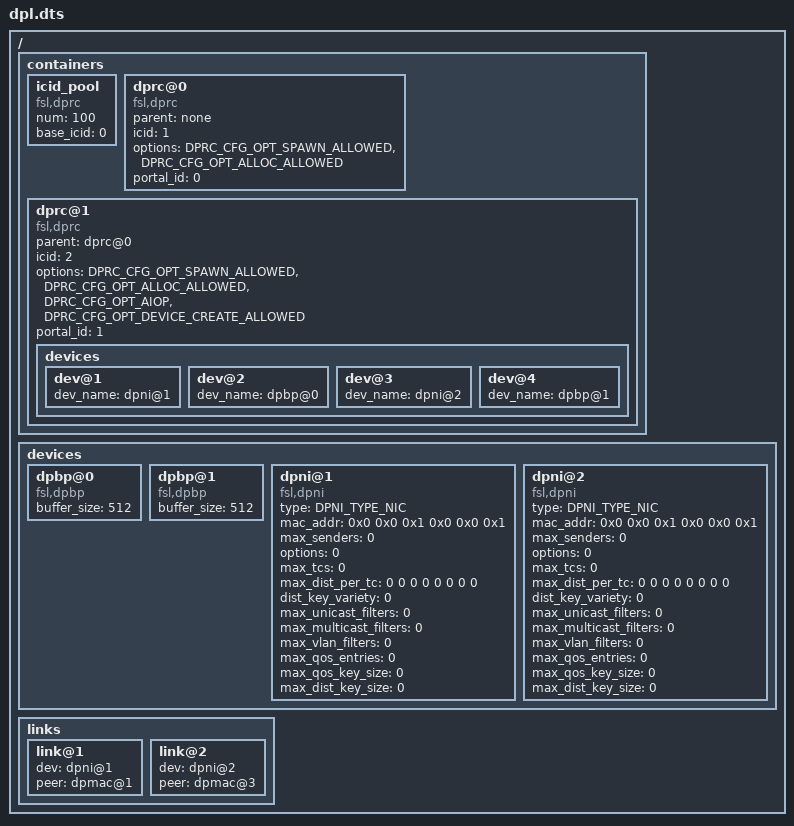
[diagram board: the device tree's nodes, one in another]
/dts-v1/;
/***************************************************************************
Example Layout:
Layout is built from 3 different sections: containers, devices, links.

1. containers - all containers are represented as : dprc@<id>.
	1.1 Container node contains:
		1.1.1 Properties required for its initialization: 
			compatible = "fsl,dprc";
			parent = "dprc@<id>"; or "none" if this is a root-level container
			options =  "string";	one or more of the following options: 
							“DPRC_CFG_OPT_SPAWN_ALLOWED”
							“DPRC_CFG_OPT_ALLOC_ALLOWED”
							“DPRC_CFG_OPT_DEVICE_CREATE_ALLOWED”
							“DPRC_CFG_OPT_TOPOLOGY_CHANGES_ALLOWED”
							“DPRC_CFG_OPT_IOMMU_BYPASS”
							“DPRC_CFG_OPT_AIOP”

			portal_id = <int>;
		1.1.2 resources - all resources are defined as follows:
			type = "string";	one of resource type defines;
			num = <int>;		Number of resources;
			options = <int>; 	Request options
			id_base_align = <int>;  In case of explicit assignment, this field represents the required base ID for resource allocation;
						In case of non-explicit assignment, this field indicates the required alignment for the resource ID(s) - use 0 or 1 if there is no alignment requirement.
		1.1.3 devices - all devices' children are built as follows:
			dev_name = "<dev>@<id>";
			portal_id = <int>;
2. devices - 	all devices' children are named: <dev>@<id> and contains all parameters required for initialization.
3. links - 	all links' children are representing two devices linked to each other. 
		
****************************************************************************/
/ {	
	containers {
		icid_pool {
			compatible = "fsl,dprc";
			num = <100>;
			base_icid = <0>;
		};
		dprc@0 {
			compatible = "fsl,dprc";
			parent = "none"; 
			icid = <1>;
			options = "DPRC_CFG_OPT_SPAWN_ALLOWED" , "DPRC_CFG_OPT_ALLOC_ALLOWED";
			portal_id = <0>;
		};
		dprc@1 {
			compatible = "fsl,dprc";
			parent = "dprc@0"; 
			icid = <2>;
			options = "DPRC_CFG_OPT_SPAWN_ALLOWED" , "DPRC_CFG_OPT_ALLOC_ALLOWED" , "DPRC_CFG_OPT_AIOP" , "DPRC_CFG_OPT_DEVICE_CREATE_ALLOWED";
			portal_id = <1>;
			devices {
				dev@1{
					dev_name = "dpni@1";
				};
				dev@2{
					dev_name = "dpbp@0";
				};
				dev@3{
					dev_name = "dpni@2";
				};
                                dev@4{
                                        dev_name = "dpbp@1";
                                };

			};
		};
	};
	devices {
                dpbp@0 {
                        compatible = "fsl,dpbp";
                        buffer_size = <512>;
                };
		dpbp@1 {
			compatible = "fsl,dpbp";
			buffer_size = <512>;
		};
		dpni@1{
			compatible = "fsl,dpni";
			type = "DPNI_TYPE_NIC";
			mac_addr = < 0x0 0x0 0x1 0x0 0x0 0x1 >;				
			max_senders = <0>;
			options = <0>;
			max_tcs = <0>;
			max_dist_per_tc = < 0 0 0 0 0 0 0 0 >; 		
			dist_key_variety = <0>;
			max_unicast_filters = <0>;
			max_multicast_filters = <0>;
			max_vlan_filters = <0>;
			max_qos_entries = <0>;
			max_qos_key_size = <0>;
			max_dist_key_size = <0>;
		};
		dpni@2{
			compatible = "fsl,dpni";
			type = "DPNI_TYPE_NIC";
			mac_addr = < 0x0 0x0 0x1 0x0 0x0 0x1 >;				
			max_senders = <0>;
			options = <0>;
			max_tcs = <0>;
			max_dist_per_tc = < 0 0 0 0 0 0 0 0 >; 		
			dist_key_variety = <0>;
			max_unicast_filters = <0>;
			max_multicast_filters = <0>;
			max_vlan_filters = <0>;
			max_qos_entries = <0>;
			max_qos_key_size = <0>;
			max_dist_key_size = <0>;
		};
	};
	links {
		link@1 {
			dev = "dpni@1";
			peer = "dpmac@1";
		};
		link@2 {
			dev = "dpni@2";
			peer = "dpmac@3";
		};
	};
};
